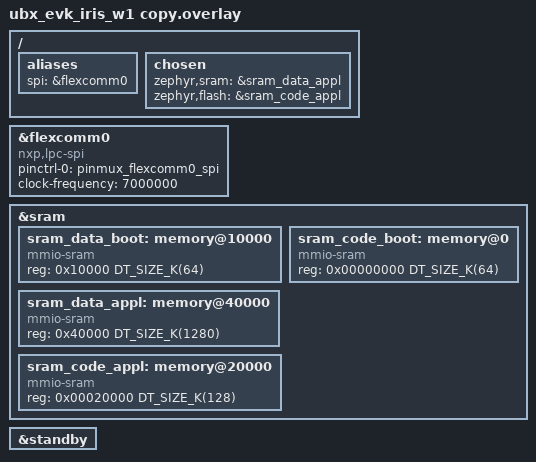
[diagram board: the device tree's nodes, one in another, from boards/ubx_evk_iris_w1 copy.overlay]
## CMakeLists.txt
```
cmake_minimum_required(VERSION 3.20.0)

set(ZEPHYR_EXTRA_MODULES 
    "${CMAKE_SOURCE_DIR}/modules/wifi_utilities" 
    "${CMAKE_SOURCE_DIR}/modules/tcp_socket"
)

find_package(Zephyr REQUIRED HINTS $ENV{ZEPHYR_BASE})
project(sample_with_mcuboot)

# Verify that this sample is built through sysbuild to ensure MCUboot is
# automatically included and that sample specific MCUboot configurations are
# used when building MCUboot.
test_sysbuild()

target_sources(app PRIVATE src/main.c)
```

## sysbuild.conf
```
# SB_CONFIG_BOOTLOADER_MCUBOOT=y
# SB_CONFIG_MCUBOOT_MODE_RAM_LOAD=y

# Enable MCUboot using overwrite only mode for this sample.
# SB_CONFIG_BOOTLOADER_MCUBOOT=y
# SB_CONFIG_MCUBOOT_MODE_OVERWRITE_ONLY=y

SB_CONFIG_BOOTLOADER_MCUBOOT=y
SB_CONFIG_MCUBOOT_MODE_RAM_LOAD=y
```

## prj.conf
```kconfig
# Remove color codes in log output
CONFIG_LOG_MODE_MINIMAL=y
CONFIG_LOG=y

# Increase stack memory to avoid crashes
CONFIG_MAIN_STACK_SIZE=8192

# Enable WiFi
CONFIG_WIFI=y

# Networking config
CONFIG_NETWORKING=y
CONFIG_NET_MGMT=y
CONFIG_NET_IPV4=y  # will rely on this in this example
CONFIG_NET_IPV6=y
CONFIG_NET_TCP=y  # For http requests
CONFIG_NET_SOCKETS=y

# CONFIG_NET_PKT_RX_COUNT=40
# CONFIG_NET_PKT_TX_COUNT=40
# CONFIG_NET_BUF_RX_COUNT=40
# CONFIG_NET_BUF_TX_COUNT=40

# Get IPv4 address from DHCP
CONFIG_NET_DHCPV4=y

# Enable DNS resolver
CONFIG_DNS_RESOLVER=y

# How long to wait for e.g., DHCP to provide an IP address (seconds)
CONFIG_NET_CONFIG_INIT_TIMEOUT=30

# Network debug config
CONFIG_NET_LOG=y

# Enable Ethernet (required for WiFi on ESP32 (do we need it for another chip?))#
# CONFIG_NET_L2_ETHERNET=y

# logging
CONFIG_LOG=y
CONFIG_LOG_MODE_IMMEDIATE=y
CONFIG_LOG_MAX_LEVEL=4

# GPIO
CONFIG_GPIO=y

# Flash
CONFIG_FLASH=y

# # SPI
# CONFIG_SPI=y
# CONFIG_SPI_ASYNC=y
# CONFIG_SPI_SLAVE=y
# CONFIG_DMA=y
# CONFIG_SPI_MCUX_FLEXCOMM=y
# CONFIG_SPI_MCUX_FLEXCOMM_DMA=y

# Enable wifi utilities
CONFIG_WIFI_UTILITIES=y

# Enable TCP socket demo
CONFIG_TCP_SOCKET=y
CONFIG_TCP_SOCKET_THREAD_STACK_SIZE=32000
```

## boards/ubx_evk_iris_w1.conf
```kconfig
CONFIG_WIFI_NXP=y
CONFIG_NXP_RW610=y

# stack size
CONFIG_HEAP_MEM_POOL_SIZE=64000

# Store binary image of blinky at the &slot0_partition address in flash
CONFIG_FLASH_BASE_ADDRESS=0x18020000
```

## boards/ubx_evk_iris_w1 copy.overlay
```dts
/*
 * Copyright 2025 u-blox AG
 *
 * SPDX-License-Identifier: Apache-2.0
 */


 &flexcomm0 {
	compatible = "nxp,lpc-spi";
	pinctrl-0 = <&pinmux_flexcomm0_spi>;
	pinctrl-names = "default";
	status = "okay";
	clock-frequency = <7000000>;
	#address-cells = <1>;
	#size-cells = <0>;
};

&sram {
	#address-cells = <1>;
	#size-cells = <1>;

	/* RW6XX SRAM can be access by either code or data bus, determined
	 * by the address used to access the memory.
	 * Applications can override the reg properties of either
	 * sram_data or sram_code nodes to change the balance of SRAM access partitioning.
	 */
	sram_data_boot: memory@10000 {
		compatible = "mmio-sram";
		reg = <0x10000 DT_SIZE_K(64)>;
	};

	sram_code_boot: memory@0 {
		compatible = "mmio-sram";
		reg = <0x00000000 DT_SIZE_K(64)>;
	};

	sram_data_appl: memory@40000 {
		compatible = "mmio-sram";
		reg = <0x40000 DT_SIZE_K(1280)>;
	};

	sram_code_appl: memory@20000 {
		compatible = "mmio-sram";
		reg = <0x00020000 DT_SIZE_K(128)>;
	};
};

/ {
	aliases {
		spi = &flexcomm0;
	};

	chosen {
		zephyr,sram = &sram_data_appl;
		zephyr,flash = &sram_code_appl;
	};
};


&standby {
	status = "okay";
};
```

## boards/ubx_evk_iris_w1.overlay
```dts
/*
 * Copyright 2025 u-blox AG
 *
 * SPDX-License-Identifier: Apache-2.0
 */


 &flexcomm0 {
	compatible = "nxp,lpc-spi";
	pinctrl-0 = <&pinmux_flexcomm0_spi>;
	pinctrl-names = "default";
	status = "okay";
	clock-frequency = <7000000>;
	#address-cells = <1>;
	#size-cells = <0>;
};

&sram {
	#address-cells = <1>;
	#size-cells = <1>;

	/* RW6XX SRAM can be access by either code or data bus, determined
	 * by the address used to access the memory.
	 * Applications can override the reg properties of either
	 * sram_data or sram_code nodes to change the balance of SRAM access partitioning.
	 */

	sram_appl: memory@0 {
		compatible = "mmio-sram";
		reg = <0x0000000 DT_SIZE_K(1088)>;
	};

	sram_boot: memory@109B00 {
		compatible = "mmio-sram";
		reg = <0x109A00 DT_SIZE_K(64)>;
	};
};

/ {
	aliases {
		spi = &flexcomm0;
		flash0 = &fm25m6413ibe;
	};

	chosen {
		zephyr,sram = &sram_appl;
		zephyr,flash = &sram_appl;
	};
};


&standby {
	status = "okay";
};
```

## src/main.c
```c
// #include <stdio.h>
// #include <string.h>
// #include <stdbool.h>
// #include <zephyr/kernel.h>
// #include <zephyr/drivers/gpio.h>
// #include <zephyr/drivers/flash.h>
// #include <zephyr/device.h>
// #include <zephyr/devicetree.h>

// #define USE_TCP 0

// #define LED0_NODE DT_ALIAS(led0)
// #define LED1_NODE DT_ALIAS(led1)
// #define LED2_NODE DT_ALIAS(led2)

// static const struct gpio_dt_spec led_red = GPIO_DT_SPEC_GET(LED0_NODE, gpios);
// static const struct gpio_dt_spec led_green = GPIO_DT_SPEC_GET(LED1_NODE, gpios);
// static const struct gpio_dt_spec led_blue = GPIO_DT_SPEC_GET(LED2_NODE, gpios);

// const int a = 5;
// volatile int b = 10;

// uint8_t data[256];
// uint8_t data_write[256];

int main(void)
{
    // const struct device *flash_dev = DEVICE_DT_GET(DT_ALIAS(flash0));
    // int ret = gpio_pin_configure_dt(&led_red, GPIO_OUTPUT_INACTIVE);
    // ret |= gpio_pin_configure_dt(&led_green, GPIO_OUTPUT_INACTIVE);
    // ret |= gpio_pin_configure_dt(&led_blue, GPIO_OUTPUT_INACTIVE);
    // uint64_t flash_size;
    // if (ret < 0) {
    //     while (1) {}
    // }
    // printk("Hello World! %p, %p\n", (void *)&a, (void *)&b);

    // ret = z_impl_flash_get_size(flash_dev, &flash_size);
    // if (ret < 0) {
    //     printk("Failed to get flash size: %d\n", ret);
    // } else {
    //     printk("Flash size: %llu bytes\n", flash_size);
    // }

    // off_t address = 0x20000 + 0x2E0000;
    // ret = z_impl_flash_erase(flash_dev, address, 256);
    // if (ret < 0) {
    //     printk("Failed to erase flash: %d\n", ret);
    // } else {
    //     printk("Flash erased successfully\n");
    // }

    // for (size_t i = 0; i < sizeof(data_write); i++) {
    //     data_write[i] = i;
    // }

    // ret = z_impl_flash_write(flash_dev, address, data_write, sizeof(data_write));
    // if (ret < 0) {
    //     printk("Failed to write flash: %d\n", ret);
    // } else {
    //     printk("Flash written successfully\n");
    // }
    
    // for (size_t i = 0; i < sizeof(data); i++) {
    //     data[i] = 0;
    // }
    // ret = z_impl_flash_read(flash_dev, address, data, 256);
    // if (ret < 0) {
    //     printk("Failed to read flash: %d\n", ret);
    // } else {
    //     printk("Read from flash:\n");
    //     for (int i = 0; i < 256; i++) {
    //         printk("%02x ", data[i]);
    //     }
    //     printk("\n");
    // }

    // while (1) {
    //     gpio_pin_set_dt(&led_red, 1);
    //     k_sleep(K_MSEC(500));
    //     gpio_pin_set_dt(&led_red, 0);
    //     k_sleep(K_MSEC(500));
    // }
}
```
